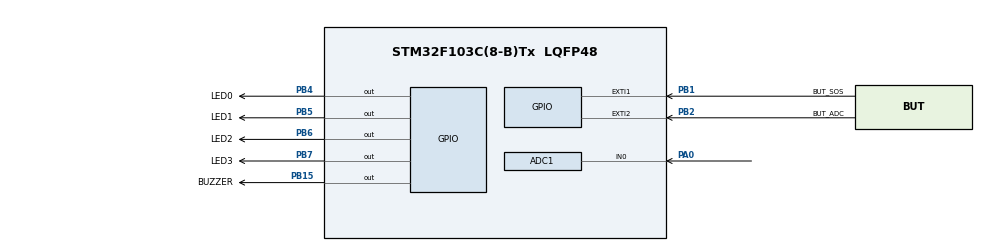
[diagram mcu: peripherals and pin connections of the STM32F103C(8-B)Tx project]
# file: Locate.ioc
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ADC1.Channel-0\#ChannelRegularConversion=ADC_CHANNEL_0
ADC1.ContinuousConvMode=ENABLE
ADC1.NbrOfConversionFlag=1
ADC1.Rank-0\#ChannelRegularConversion=1
ADC1.SamplingTime-0\#ChannelRegularConversion=ADC_SAMPLETIME_41CYCLES_5
ADC1.master=1
Mcu.Family=STM32F1
Mcu.Name=STM32F103C(8-B)Tx
Mcu.Package=LQFP48
NVIC.EXTI1_IRQn=true\:3\:0\:true\:false\:true\:true\:true\:true
NVIC.EXTI2_IRQn=true\:4\:0\:true\:false\:true\:true\:true\:true
NVIC.PriorityGroup=NVIC_PRIORITYGROUP_4
NVIC.TIM2_IRQn=true\:1\:0\:true\:false\:true\:true\:true\:true
PA0-WKUP.Signal=ADCx_IN0
PA13.Mode=Serial_Wire
PA13.Signal=SYS_JTMS-SWDIO
PA14.Mode=Serial_Wire
PA14.Signal=SYS_JTCK-SWCLK
PB1.GPIO_Label=BUT_SOS
PB1.GPIO_ModeDefaultEXTI=GPIO_MODE_IT_FALLING
PB1.GPIO_PuPd=GPIO_PULLUP
PB1.Signal=GPXTI1
PB15.GPIO_Label=BUZZER
PB15.PinState=GPIO_PIN_RESET
PB15.Signal=GPIO_Output
PB2.GPIO_Label=BUT_ADC
PB2.GPIO_ModeDefaultEXTI=GPIO_MODE_IT_FALLING
PB2.GPIO_PuPd=GPIO_PULLUP
PB2.Signal=GPXTI2
PB4.GPIO_Label=LED0
PB4.PinState=GPIO_PIN_SET
PB4.Signal=GPIO_Output
PB5.GPIO_Label=LED1
PB5.PinState=GPIO_PIN_SET
PB5.Signal=GPIO_Output
PB6.GPIO_Label=LED2
PB6.PinState=GPIO_PIN_SET
PB6.Signal=GPIO_Output
PB7.GPIO_Label=LED3
PB7.PinState=GPIO_PIN_SET
PB7.Signal=GPIO_Output
PD0-OSC_IN.Mode=HSE-External-Oscillator
PD0-OSC_IN.Signal=RCC_OSC_IN
PD1-OSC_OUT.Mode=HSE-External-Oscillator
PD1-OSC_OUT.Signal=RCC_OSC_OUT
ProjectManager.HeapSize=0x200
ProjectManager.StackSize=0x400
ProjectManager.TargetToolchain=Makefile
RCC.APB1Freq_Value=8000000
RCC.APB2Freq_Value=8000000
SH.ADCx_IN0.0=ADC1_IN0,IN0
TIM2.AutoReloadPreload=TIM_AUTORELOAD_PRELOAD_ENABLE
TIM2.Period=2999
TIM2.Prescaler=8000
VP_TIM2_VS_ClockSourceINT.Mode=Internal
board=custom

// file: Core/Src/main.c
/* USER CODE BEGIN Header */
/**
  ******************************************************************************
  * @file           : main.c
  * @brief          : Main program body
  ******************************************************************************
  * @attention
  *
  * Copyright (c) 2022 STMicroelectronics.
  * All rights reserved.
  *
  * This software is licensed under terms that can be found in the LICENSE file
  * in the root directory of this software component.
  * If no LICENSE file comes with this software, it is provided AS-IS.
  *
  ******************************************************************************
  */
/* USER CODE END Header */
#include "main.h"
#include "adc.h"
#include "tim.h"
#include "gpio.h"

/* USER CODE BEGIN Includes */
#include "checkpin.h"
/* USER CODE END Includes */

void SystemClock_Config(void);

int main(void)
{

  /* MCU Configuration--------------------------------------------------------*/

  /* Reset of all peripherals, Initializes the Flash interface and the Systick. */
  HAL_Init();

  /* Configure the system clock */
  SystemClock_Config();

  /* Initialize all configured peripherals */
  MX_GPIO_Init();
  MX_ADC1_Init();
  MX_TIM2_Init();
  /* USER CODE BEGIN 2 */
  HAL_ADC_Start(&hadc1);
  /* USER CODE END 2 */

  /* Infinite loop */
  while (1)
  {

  }
}

void SystemClock_Config(void)
{
  RCC_OscInitTypeDef RCC_OscInitStruct = {0};
  RCC_ClkInitTypeDef RCC_ClkInitStruct = {0};
  RCC_PeriphCLKInitTypeDef PeriphClkInit = {0};

  /** Initializes the RCC Oscillators according to the specified parameters
  * in the RCC_OscInitTypeDef structure.
  */
  RCC_OscInitStruct.OscillatorType = RCC_OSCILLATORTYPE_HSI;
  RCC_OscInitStruct.HSIState = RCC_HSI_ON;
  RCC_OscInitStruct.HSICalibrationValue = RCC_HSICALIBRATION_DEFAULT;
  RCC_OscInitStruct.PLL.PLLState = RCC_PLL_NONE;
  if (HAL_RCC_OscConfig(&RCC_OscInitStruct) != HAL_OK)
  {
    Error_Handler();
  }

  /** Initializes the CPU, AHB and APB buses clocks
  */
  RCC_ClkInitStruct.ClockType = RCC_CLOCKTYPE_HCLK|RCC_CLOCKTYPE_SYSCLK
                              |RCC_CLOCKTYPE_PCLK1|RCC_CLOCKTYPE_PCLK2;
  RCC_ClkInitStruct.SYSCLKSource = RCC_SYSCLKSOURCE_HSI;
  RCC_ClkInitStruct.AHBCLKDivider = RCC_SYSCLK_DIV1;
  RCC_ClkInitStruct.APB1CLKDivider = RCC_HCLK_DIV1;
  RCC_ClkInitStruct.APB2CLKDivider = RCC_HCLK_DIV1;

  if (HAL_RCC_ClockConfig(&RCC_ClkInitStruct, FLASH_LATENCY_0) != HAL_OK)
  {
    Error_Handler();
  }
  PeriphClkInit.PeriphClockSelection = RCC_PERIPHCLK_ADC;
  PeriphClkInit.AdcClockSelection = RCC_ADCPCLK2_DIV2;
  if (HAL_RCCEx_PeriphCLKConfig(&PeriphClkInit) != HAL_OK)
  {
    Error_Handler();
  }
}

void Error_Handler(void)
{
  __disable_irq();
  while (1)
  {
  }
}
